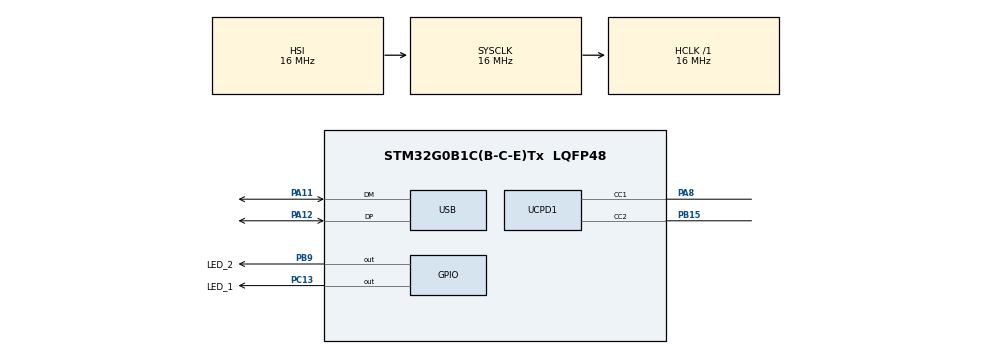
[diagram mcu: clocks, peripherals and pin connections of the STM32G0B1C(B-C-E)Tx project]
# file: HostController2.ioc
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FREERTOS.Tasks01=defaultTask,24,128,StartDefaultTask,Default,NULL,Dynamic,NULL,NULL
FREERTOS.configUSE_NEWLIB_REENTRANT=1
Mcu.Family=STM32G0
Mcu.Name=STM32G0B1C(B-C-E)Tx
Mcu.Package=LQFP48
NVIC.TIM1_BRK_UP_TRG_COM_IRQn=true\:3\:0\:false\:false\:true\:false\:false\:true\:true
NVIC.TimeBase=TIM1_BRK_UP_TRG_COM_IRQn
NVIC.TimeBaseIP=TIM1
PA11\ [PA9].Mode=Device
PA11\ [PA9].Signal=USB_DM
PA12\ [PA10].Mode=Device
PA12\ [PA10].Signal=USB_DP
PA13.Mode=Serial_Wire
PA13.Signal=SYS_SWDIO
PA14-BOOT0.Mode=Serial_Wire
PA14-BOOT0.Signal=SYS_SWCLK
PA8.Mode=Sink_AllSignals
PA8.Signal=UCPD1_CC1
PB15.Mode=Sink_AllSignals
PB15.Signal=UCPD1_CC2
PB9.GPIO_Label=LED_2
PB9.PinState=GPIO_PIN_SET
PB9.Signal=GPIO_Output
PC13.GPIO_Label=LED_1
PC13.PinState=GPIO_PIN_SET
PC13.Signal=GPIO_Output
ProjectManager.HeapSize=0x200
ProjectManager.StackSize=0x400
ProjectManager.TargetToolchain=STM32CubeIDE
RCC.AHBFreq_Value=16000000
RCC.CortexFreq_Value=16000000
RCC.EXTERNAL_CLOCK_VALUE=48000
RCC.HCLKFreq_Value=16000000
RCC.HSE_VALUE=8000000
RCC.HSI48_VALUE=48000000
RCC.HSI_VALUE=16000000
RCC.LSE_VALUE=32768
RCC.SYSCLKFreq_VALUE=16000000
RCC.USBFreq_Value=48000000
RCC.VCOOutputFreq_Value=128000000
VP_FREERTOS_VS_CMSIS_V2.Mode=CMSIS_V2
VP_SYS_VS_DBSignals.Mode=DisableDeadBatterySignals
VP_SYS_VS_tim1.Mode=TIM1
board=custom

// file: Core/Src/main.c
/* USER CODE BEGIN Header */
/**
  ******************************************************************************
  * @file           : main.c
  * @brief          : Main program body
  ******************************************************************************
  * @attention
  *
  * Copyright (c) 2026 STMicroelectronics.
  * All rights reserved.
  *
  * This software is licensed under terms that can be found in the LICENSE file
  * in the root directory of this software component.
  * If no LICENSE file comes with this software, it is provided AS-IS.
  *
  ******************************************************************************
  */
/* USER CODE END Header */
#include "main.h"
#include "cmsis_os.h"

/* USER CODE BEGIN Includes */
#include <AstroWeather.hpp>
/* USER CODE END Includes */

PCD_HandleTypeDef hpcd_USB_DRD_FS;

/* Definitions for defaultTask */
osThreadId_t defaultTaskHandle;
const osThreadAttr_t defaultTask_attributes = {
  .name = "defaultTask",
  .priority = (osPriority_t) osPriorityNormal,
  .stack_size = 128 * 4
};

void SystemClock_Config(void);
static void MX_GPIO_Init(void);
static void MX_UCPD1_Init(void);
static void MX_USB_DRD_FS_PCD_Init(void);
void StartDefaultTask(void *argument);

int main(void)
{

  /* MCU Configuration--------------------------------------------------------*/

  /* Reset of all peripherals, Initializes the Flash interface and the Systick. */
  HAL_Init();

  /* Configure the system clock */
  SystemClock_Config();

  /* Initialize all configured peripherals */
  MX_GPIO_Init();
  MX_UCPD1_Init();
  MX_USB_DRD_FS_PCD_Init();

  /* Init scheduler */
  osKernelInitialize();

  /* Create the thread(s) */
  /* creation of defaultTask */
  defaultTaskHandle = osThreadNew(StartDefaultTask, NULL, &defaultTask_attributes);

  /* USER CODE BEGIN RTOS_THREADS */
  AstroWeather_Init();
  /* USER CODE END RTOS_THREADS */

  /* Start scheduler */
  osKernelStart();

  /* We should never get here as control is now taken by the scheduler */

  /* Infinite loop */
  while (1)
  {

  }
}

void SystemClock_Config(void)
{
  RCC_OscInitTypeDef RCC_OscInitStruct = {0};
  RCC_ClkInitTypeDef RCC_ClkInitStruct = {0};

  /** Configure the main internal regulator output voltage
  */
  HAL_PWREx_ControlVoltageScaling(PWR_REGULATOR_VOLTAGE_SCALE1);

  /** Initializes the RCC Oscillators according to the specified parameters
  * in the RCC_OscInitTypeDef structure.
  */
  RCC_OscInitStruct.OscillatorType = RCC_OSCILLATORTYPE_HSI|RCC_OSCILLATORTYPE_HSI48;
  RCC_OscInitStruct.HSIState = RCC_HSI_ON;
  RCC_OscInitStruct.HSI48State = RCC_HSI48_ON;
  RCC_OscInitStruct.HSIDiv = RCC_HSI_DIV1;
  RCC_OscInitStruct.HSICalibrationValue = RCC_HSICALIBRATION_DEFAULT;
  RCC_OscInitStruct.PLL.PLLState = RCC_PLL_NONE;
  if (HAL_RCC_OscConfig(&RCC_OscInitStruct) != HAL_OK)
  {
    Error_Handler();
  }

  /** Initializes the CPU, AHB and APB buses clocks
  */
  RCC_ClkInitStruct.ClockType = RCC_CLOCKTYPE_HCLK|RCC_CLOCKTYPE_SYSCLK
                              |RCC_CLOCKTYPE_PCLK1;
  RCC_ClkInitStruct.SYSCLKSource = RCC_SYSCLKSOURCE_HSI;
  RCC_ClkInitStruct.AHBCLKDivider = RCC_SYSCLK_DIV1;
  RCC_ClkInitStruct.APB1CLKDivider = RCC_HCLK_DIV1;

  if (HAL_RCC_ClockConfig(&RCC_ClkInitStruct, FLASH_LATENCY_0) != HAL_OK)
  {
    Error_Handler();
  }
}

static void MX_UCPD1_Init(void)
{

  LL_GPIO_InitTypeDef GPIO_InitStruct = {0};

  /* Peripheral clock enable */
  LL_APB1_GRP1_EnableClock(LL_APB1_GRP1_PERIPH_UCPD1);

  LL_IOP_GRP1_EnableClock(LL_IOP_GRP1_PERIPH_GPIOB);
  LL_IOP_GRP1_EnableClock(LL_IOP_GRP1_PERIPH_GPIOA);
  /**UCPD1 GPIO Configuration
  PB15   ------> UCPD1_CC2
  PA8   ------> UCPD1_CC1
  */
  GPIO_InitStruct.Pin = LL_GPIO_PIN_15;
  GPIO_InitStruct.Mode = LL_GPIO_MODE_ANALOG;
  GPIO_InitStruct.Pull = LL_GPIO_PULL_NO;
  LL_GPIO_Init(GPIOB, &GPIO_InitStruct);

  GPIO_InitStruct.Pin = LL_GPIO_PIN_8;
  GPIO_InitStruct.Mode = LL_GPIO_MODE_ANALOG;
  GPIO_InitStruct.Pull = LL_GPIO_PULL_NO;
  LL_GPIO_Init(GPIOA, &GPIO_InitStruct);

}

static void MX_USB_DRD_FS_PCD_Init(void)
{

  hpcd_USB_DRD_FS.Instance = USB_DRD_FS;
  hpcd_USB_DRD_FS.Init.dev_endpoints = 8;
  hpcd_USB_DRD_FS.Init.Host_channels = 8;
  hpcd_USB_DRD_FS.Init.speed = PCD_SPEED_FULL;
  hpcd_USB_DRD_FS.Init.phy_itface = PCD_PHY_EMBEDDED;
  hpcd_USB_DRD_FS.Init.Sof_enable = DISABLE;
  hpcd_USB_DRD_FS.Init.low_power_enable = DISABLE;
  hpcd_USB_DRD_FS.Init.lpm_enable = DISABLE;
  hpcd_USB_DRD_FS.Init.battery_charging_enable = DISABLE;
  hpcd_USB_DRD_FS.Init.vbus_sensing_enable = DISABLE;
  hpcd_USB_DRD_FS.Init.bulk_doublebuffer_enable = DISABLE;
  hpcd_USB_DRD_FS.Init.iso_singlebuffer_enable = DISABLE;
  if (HAL_PCD_Init(&hpcd_USB_DRD_FS) != HAL_OK)
  {
    Error_Handler();
  }

}

static void MX_GPIO_Init(void)
{
  GPIO_InitTypeDef GPIO_InitStruct = {0};

  /* GPIO Ports Clock Enable */
  __HAL_RCC_GPIOC_CLK_ENABLE();
  __HAL_RCC_GPIOB_CLK_ENABLE();
  __HAL_RCC_GPIOA_CLK_ENABLE();

  /*Configure GPIO pin Output Level */
  HAL_GPIO_WritePin(LED_1_GPIO_Port, LED_1_Pin, GPIO_PIN_SET);

  /*Configure GPIO pin Output Level */
  HAL_GPIO_WritePin(LED_2_GPIO_Port, LED_2_Pin, GPIO_PIN_SET);

  /*Configure GPIO pin : LED_1_Pin */
  GPIO_InitStruct.Pin = LED_1_Pin;
  GPIO_InitStruct.Mode = GPIO_MODE_OUTPUT_PP;
  GPIO_InitStruct.Pull = GPIO_NOPULL;
  GPIO_InitStruct.Speed = GPIO_SPEED_FREQ_LOW;
  HAL_GPIO_Init(LED_1_GPIO_Port, &GPIO_InitStruct);

  /*Configure GPIO pin : LED_2_Pin */
  GPIO_InitStruct.Pin = LED_2_Pin;
  GPIO_InitStruct.Mode = GPIO_MODE_OUTPUT_PP;
  GPIO_InitStruct.Pull = GPIO_NOPULL;
  GPIO_InitStruct.Speed = GPIO_SPEED_FREQ_LOW;
  HAL_GPIO_Init(LED_2_GPIO_Port, &GPIO_InitStruct);

}

void StartDefaultTask(void *argument)
{
  /* USER CODE BEGIN 5 */
  /* Infinite loop */
  for(;;)
  {
    HAL_GPIO_TogglePin(LED_1_GPIO_Port, LED_1_Pin);
    osDelay(250);
    HAL_GPIO_TogglePin(LED_2_GPIO_Port, LED_2_Pin);
  }
  /* USER CODE END 5 */
}

void HAL_TIM_PeriodElapsedCallback(TIM_HandleTypeDef *htim)
{
  if (htim->Instance == TIM1)
  {
    HAL_IncTick();
  }
}

void Error_Handler(void)
{
  __disable_irq();
  while (1)
  {
  }
}
